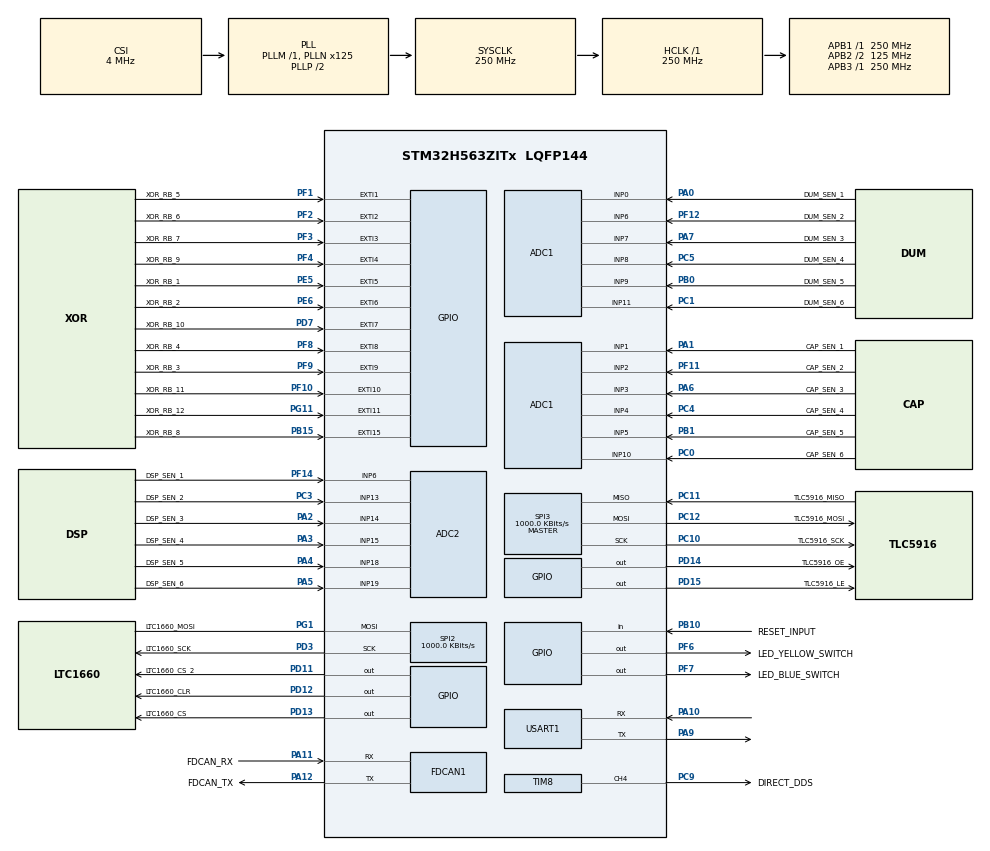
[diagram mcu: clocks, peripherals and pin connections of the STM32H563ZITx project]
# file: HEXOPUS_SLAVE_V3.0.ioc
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ADC1.Channel-10\#ChannelRegularConversion=ADC_CHANNEL_2
ADC1.Channel-11\#ChannelRegularConversion=ADC_CHANNEL_6
ADC1.Channel-12\#ChannelRegularConversion=ADC_CHANNEL_3
ADC1.Channel-13\#ChannelRegularConversion=ADC_CHANNEL_7
ADC1.Channel-14\#ChannelRegularConversion=ADC_CHANNEL_4
ADC1.Channel-15\#ChannelRegularConversion=ADC_CHANNEL_8
ADC1.Channel-16\#ChannelRegularConversion=ADC_CHANNEL_5
ADC1.Channel-17\#ChannelRegularConversion=ADC_CHANNEL_9
ADC1.Channel-18\#ChannelRegularConversion=ADC_CHANNEL_10
ADC1.Channel-19\#ChannelRegularConversion=ADC_CHANNEL_11
ADC1.Channel-8\#ChannelRegularConversion=ADC_CHANNEL_1
ADC1.Channel-9\#ChannelRegularConversion=ADC_CHANNEL_0
ADC1.ClockPrescaler=ADC_CLOCK_ASYNC_DIV2
ADC1.ContinuousConvMode=ENABLE
ADC1.DMAContinuousRequests=ENABLE
ADC1.MonitoredBy-10\#ChannelRegularConversion=__NULL
ADC1.MonitoredBy-11\#ChannelRegularConversion=__NULL
ADC1.MonitoredBy-12\#ChannelRegularConversion=__NULL
ADC1.MonitoredBy-13\#ChannelRegularConversion=__NULL
ADC1.MonitoredBy-14\#ChannelRegularConversion=__NULL
ADC1.MonitoredBy-15\#ChannelRegularConversion=__NULL
ADC1.MonitoredBy-16\#ChannelRegularConversion=__NULL
ADC1.MonitoredBy-17\#ChannelRegularConversion=__NULL
ADC1.MonitoredBy-18\#ChannelRegularConversion=__NULL
ADC1.MonitoredBy-19\#ChannelRegularConversion=__NULL
ADC1.MonitoredBy-8\#ChannelRegularConversion=__NULL
ADC1.MonitoredBy-9\#ChannelRegularConversion=__NULL
ADC1.NbrOfConversion=12
ADC1.NbrOfConversionFlag=1
ADC1.OffsetNumber-10\#ChannelRegularConversion=ADC_OFFSET_NONE
ADC1.OffsetNumber-11\#ChannelRegularConversion=ADC_OFFSET_NONE
ADC1.OffsetNumber-12\#ChannelRegularConversion=ADC_OFFSET_NONE
ADC1.OffsetNumber-13\#ChannelRegularConversion=ADC_OFFSET_NONE
ADC1.OffsetNumber-14\#ChannelRegularConversion=ADC_OFFSET_NONE
ADC1.OffsetNumber-15\#ChannelRegularConversion=ADC_OFFSET_NONE
ADC1.OffsetNumber-16\#ChannelRegularConversion=ADC_OFFSET_NONE
ADC1.OffsetNumber-17\#ChannelRegularConversion=ADC_OFFSET_NONE
ADC1.OffsetNumber-18\#ChannelRegularConversion=ADC_OFFSET_NONE
ADC1.OffsetNumber-19\#ChannelRegularConversion=ADC_OFFSET_NONE
ADC1.OffsetNumber-8\#ChannelRegularConversion=ADC_OFFSET_NONE
ADC1.OffsetNumber-9\#ChannelRegularConversion=ADC_OFFSET_NONE
ADC1.Rank-10\#ChannelRegularConversion=3
ADC1.Rank-11\#ChannelRegularConversion=4
ADC1.Rank-12\#ChannelRegularConversion=5
ADC1.Rank-13\#ChannelRegularConversion=6
ADC1.Rank-14\#ChannelRegularConversion=7
ADC1.Rank-15\#ChannelRegularConversion=8
ADC1.Rank-16\#ChannelRegularConversion=9
ADC1.Rank-17\#ChannelRegularConversion=10
ADC1.Rank-18\#ChannelRegularConversion=11
ADC1.Rank-19\#ChannelRegularConversion=12
ADC1.Rank-8\#ChannelRegularConversion=1
ADC1.Rank-9\#ChannelRegularConversion=2
ADC1.SamplingTime-10\#ChannelRegularConversion=ADC_SAMPLETIME_92CYCLES_5
ADC1.SamplingTime-11\#ChannelRegularConversion=ADC_SAMPLETIME_92CYCLES_5
ADC1.SamplingTime-12\#ChannelRegularConversion=ADC_SAMPLETIME_92CYCLES_5
ADC1.SamplingTime-13\#ChannelRegularConversion=ADC_SAMPLETIME_92CYCLES_5
ADC1.SamplingTime-14\#ChannelRegularConversion=ADC_SAMPLETIME_92CYCLES_5
ADC1.SamplingTime-15\#ChannelRegularConversion=ADC_SAMPLETIME_92CYCLES_5
ADC1.SamplingTime-16\#ChannelRegularConversion=ADC_SAMPLETIME_92CYCLES_5
ADC1.SamplingTime-17\#ChannelRegularConversion=ADC_SAMPLETIME_92CYCLES_5
ADC1.SamplingTime-18\#ChannelRegularConversion=ADC_SAMPLETIME_92CYCLES_5
ADC1.SamplingTime-19\#ChannelRegularConversion=ADC_SAMPLETIME_92CYCLES_5
ADC1.SamplingTime-8\#ChannelRegularConversion=ADC_SAMPLETIME_92CYCLES_5
ADC1.SamplingTime-9\#ChannelRegularConversion=ADC_SAMPLETIME_92CYCLES_5
ADC1.master=1
ADC2.Channel-18\#ChannelRegularConversion=ADC_CHANNEL_6
ADC2.Channel-19\#ChannelRegularConversion=ADC_CHANNEL_13
ADC2.Channel-20\#ChannelRegularConversion=ADC_CHANNEL_14
ADC2.Channel-21\#ChannelRegularConversion=ADC_CHANNEL_15
ADC2.Channel-22\#ChannelRegularConversion=ADC_CHANNEL_18
ADC2.Channel-23\#ChannelRegularConversion=ADC_CHANNEL_19
ADC2.ClockPrescaler=ADC_CLOCK_ASYNC_DIV2
ADC2.ContinuousConvMode=ENABLE
ADC2.DMAContinuousRequests=ENABLE
ADC2.MonitoredBy-18\#ChannelRegularConversion=__NULL
ADC2.MonitoredBy-19\#ChannelRegularConversion=__NULL
ADC2.MonitoredBy-20\#ChannelRegularConversion=__NULL
ADC2.MonitoredBy-21\#ChannelRegularConversion=__NULL
ADC2.MonitoredBy-22\#ChannelRegularConversion=__NULL
ADC2.MonitoredBy-23\#ChannelRegularConversion=__NULL
ADC2.NbrOfConversion=6
ADC2.NbrOfConversionFlag=1
ADC2.OffsetNumber-18\#ChannelRegularConversion=ADC_OFFSET_NONE
ADC2.OffsetNumber-19\#ChannelRegularConversion=ADC_OFFSET_NONE
ADC2.OffsetNumber-20\#ChannelRegularConversion=ADC_OFFSET_NONE
ADC2.OffsetNumber-21\#ChannelRegularConversion=ADC_OFFSET_NONE
ADC2.OffsetNumber-22\#ChannelRegularConversion=ADC_OFFSET_NONE
ADC2.OffsetNumber-23\#ChannelRegularConversion=ADC_OFFSET_NONE
ADC2.Rank-18\#ChannelRegularConversion=1
ADC2.Rank-19\#ChannelRegularConversion=2
ADC2.Rank-20\#ChannelRegularConversion=3
ADC2.Rank-21\#ChannelRegularConversion=4
ADC2.Rank-22\#ChannelRegularConversion=5
ADC2.Rank-23\#ChannelRegularConversion=6
ADC2.SamplingTime-18\#ChannelRegularConversion=ADC_SAMPLETIME_92CYCLES_5
ADC2.SamplingTime-19\#ChannelRegularConversion=ADC_SAMPLETIME_92CYCLES_5
ADC2.SamplingTime-20\#ChannelRegularConversion=ADC_SAMPLETIME_92CYCLES_5
ADC2.SamplingTime-21\#ChannelRegularConversion=ADC_SAMPLETIME_92CYCLES_5
ADC2.SamplingTime-22\#ChannelRegularConversion=ADC_SAMPLETIME_92CYCLES_5
ADC2.SamplingTime-23\#ChannelRegularConversion=ADC_SAMPLETIME_92CYCLES_5
BOOTPATH.BootPathName=LEGACY
BOOTPATH.UserSelectedBootPath=LEGACY
CORTEX_M33_NS.userName=CORTEX_M33
FDCAN1.AutoRetransmission=ENABLE
FDCAN1.CalculateBaudRateNominal=250000
FDCAN1.CalculateTimeBitNominal=4000
FDCAN1.CalculateTimeQuantumNominal=40.0
FDCAN1.ClockDivider=FDCAN_CLOCK_DIV1
FDCAN1.FrameFormat=FDCAN_FRAME_FD_NO_BRS
FDCAN1.NominalPrescaler=2
FDCAN1.NominalSyncJumpWidth=20
FDCAN1.NominalTimeSeg1=79
FDCAN1.NominalTimeSeg2=20
FDCAN1.StdFiltersNbr=1
FDCAN1.TransmitPause=ENABLE
GPDMA1.CIRCULARMODE_GPDMACH7=ENABLE
GPDMA1.DESTDATAWIDTH_GPDMACH7=DMA_DEST_DATAWIDTH_WORD
GPDMA1.DESTINC_GPDMACH7=DMA_DINC_INCREMENTED
GPDMA1.IPHANDLE_GPDMACH7-SIMPLEREQUEST_GPDMACH7=__NULL
GPDMA1.REQUEST_GPDMACH7=GPDMA1_REQUEST_ADC1
GPDMA1.SRCDATAWIDTH_GPDMACH7=DMA_SRC_DATAWIDTH_HALFWORD
GPDMA2.CIRCULARMODE_GPDMACH7=ENABLE
GPDMA2.DESTDATAWIDTH_GPDMACH7=DMA_DEST_DATAWIDTH_WORD
GPDMA2.DESTINC_GPDMACH7=DMA_DINC_INCREMENTED
GPDMA2.IPHANDLE_GPDMACH7-SIMPLEREQUEST_GPDMACH7=__NULL
GPDMA2.REQUEST_GPDMACH7=GPDMA2_REQUEST_ADC2
GPDMA2.SRCDATAWIDTH_GPDMACH7=DMA_SRC_DATAWIDTH_HALFWORD
Mcu.Family=STM32H5
Mcu.Name=STM32H563ZITx
Mcu.Package=LQFP144
NVIC.FDCAN1_IT0_IRQn=true\:0\:0\:false\:false\:true\:true\:true\:true
NVIC.GPDMA1_Channel7_IRQn=true\:0\:0\:false\:false\:true\:false\:true\:true
NVIC.GPDMA2_Channel7_IRQn=true\:0\:0\:false\:false\:true\:false\:true\:true
NVIC.PriorityGroup=NVIC_PRIORITYGROUP_4
NVIC.TIM12_IRQn=true\:15\:0\:true\:false\:true\:true\:true\:true
NVIC.TIM2_IRQn=true\:1\:0\:true\:false\:true\:true\:true\:true
NVIC.TIM3_IRQn=true\:0\:0\:false\:false\:true\:true\:true\:true
NVIC.TIM4_IRQn=true\:3\:0\:true\:false\:true\:true\:true\:true
NVIC.TIM5_IRQn=true\:2\:0\:true\:false\:true\:true\:true\:true
NVIC.USART1_IRQn=true\:4\:0\:true\:false\:true\:true\:true\:true
PA0.GPIO_Label=DUM_SEN_1
PA0.Signal=ADCx_INP0
PA1.GPIO_Label=CAP_SEN_1
PA1.Signal=ADCx_INP1
PA10.Mode=Asynchronous
PA10.Signal=USART1_RX
PA11.GPIO_Label=FDCAN_RX
PA11.Mode=FDCAN_Activate
PA11.Signal=FDCAN1_RX
PA12.GPIO_Label=FDCAN_TX
PA12.Mode=FDCAN_Activate
PA12.Signal=FDCAN1_TX
PA2.GPIO_Label=DSP_SEN_3
PA2.Signal=ADCx_INP14
PA3.GPIO_Label=DSP_SEN_4
PA3.Signal=ADCx_INP15
PA4.GPIO_Label=DSP_SEN_5
PA4.Signal=ADCx_INP18
PA5.GPIO_Label=DSP_SEN_6
PA5.Signal=ADCx_INP19
PA6.GPIO_Label=CAP_SEN_3
PA6.Signal=ADCx_INP3
PA7.GPIO_Label=DUM_SEN_3
PA7.Signal=ADCx_INP7
PA9.Mode=Asynchronous
PA9.Signal=USART1_TX
PB0.GPIO_Label=DUM_SEN_5
PB0.Signal=ADCx_INP9
PB1.GPIO_Label=CAP_SEN_5
PB1.Signal=ADCx_INP5
PB10.GPIO_Label=RESET_INPUT
PB10.Signal=GPIO_Input
PB12.GPIO_Label=FDCAN_AUX_RX
PB12.Signal=FDCAN2_RX
PB15.GPIO_Label=XOR_RB_8
PB15.Signal=GPXTI15
PC0.GPIO_Label=CAP_SEN_6
PC0.Signal=ADCx_INP10
PC1.GPIO_Label=DUM_SEN_6
PC1.Signal=ADCx_INP11
PC10.GPIO_Label=TLC5916_SCK
PC10.Mode=Full_Duplex_Master
PC10.Signal=SPI3_SCK
PC11.GPIO_Label=TLC5916_MISO
PC11.Mode=Full_Duplex_Master
PC11.Signal=SPI3_MISO
PC12.GPIO_Label=TLC5916_MOSI
PC12.Mode=Full_Duplex_Master
PC12.Signal=SPI3_MOSI
PC3.GPIO_Label=DSP_SEN_2
PC3.Signal=ADCx_INP13
PC4.GPIO_Label=CAP_SEN_4
PC4.Signal=ADCx_INP4
PC5.GPIO_Label=DUM_SEN_4
PC5.Signal=ADCx_INP8
PC9.GPIO_Label=DIRECT_DDS
PC9.GPIO_Speed=GPIO_SPEED_FREQ_VERY_HIGH
PC9.Signal=S_TIM8_CH4
PD11.GPIO_Label=LTC1660_CS_2
PD11.PinState=GPIO_PIN_RESET
PD11.Signal=GPIO_Output
PD12.GPIO_Label=LTC1660_CLR
PD12.PinState=GPIO_PIN_SET
PD12.Signal=GPIO_Output
PD13.GPIO_Label=LTC1660_CS
PD13.Signal=GPIO_Output
PD14.GPIO_Label=TLC5916_OE
PD14.Signal=GPIO_Output
PD15.GPIO_Label=TLC5916_LE
PD15.Signal=GPIO_Output
PD3.GPIO_Label=LTC1660_SCK
PD3.GPIO_PuPd=GPIO_PULLDOWN
PD3.GPIO_Speed=GPIO_SPEED_FREQ_VERY_HIGH
PD3.Mode=Simplex_Bidirectional_Master
PD3.Signal=SPI2_SCK
PD7.GPIO_Label=XOR_RB_10
PD7.Signal=GPXTI7
PE5.GPIO_Label=XOR_RB_1
PE5.Signal=GPXTI5
PE6.GPIO_Label=XOR_RB_2
PE6.Signal=GPXTI6
PF1.GPIO_Label=XOR_RB_5
PF1.Signal=GPXTI1
PF10.GPIO_Label=XOR_RB_11
PF10.Signal=GPXTI10
PF11.GPIO_Label=CAP_SEN_2
PF11.Mode=IN2-Single-Ended
PF11.Signal=ADC1_INP2
PF12.GPIO_Label=DUM_SEN_2
PF12.Mode=IN6-Single-Ended
PF12.Signal=ADC1_INP6
PF14.GPIO_Label=DSP_SEN_1
PF14.Mode=IN6-Single-Ended
PF14.Signal=ADC2_INP6
PF2.GPIO_Label=XOR_RB_6
PF2.Signal=GPXTI2
PF3.GPIO_Label=XOR_RB_7
PF3.Signal=GPXTI3
PF4.GPIO_Label=XOR_RB_9
PF4.Signal=GPXTI4
PF6.GPIO_Label=LED_YELLOW_SWITCH
PF6.Signal=GPIO_Output
PF7.GPIO_Label=LED_BLUE_SWITCH
PF7.Signal=GPIO_Output
PF8.GPIO_Label=XOR_RB_4
PF8.Signal=GPXTI8
PF9.GPIO_Label=XOR_RB_3
PF9.Signal=GPXTI9
PG1.GPIO_Label=LTC1660_MOSI
PG1.GPIO_PuPd=GPIO_PULLDOWN
PG1.GPIO_Speed=GPIO_SPEED_FREQ_VERY_HIGH
PG1.Mode=Simplex_Bidirectional_Master
PG1.Signal=SPI2_MOSI
PG11.GPIO_Label=XOR_RB_12
PG11.Signal=GPXTI11
ProjectManager.HeapSize=0x200
ProjectManager.StackSize=0x400
ProjectManager.TargetToolchain=STM32CubeIDE
RCC.ADCCLockSelection=RCC_ADCDACCLKSOURCE_HSI
RCC.ADCFreq_Value=64000000
RCC.AHBFreq_Value=250000000
RCC.APB1Freq_Value=250000000
RCC.APB1TimFreq_Value=250000000
RCC.APB2CLKDivider=RCC_HCLK_DIV2
RCC.APB2Freq_Value=125000000
RCC.APB2TimFreq_Value=250000000
RCC.APB3Freq_Value=250000000
RCC.CKPERSourceSelection=RCC_CLKPSOURCE_HSI
RCC.CSI_VALUE=4000000
RCC.CortexFreq_Value=250000000
RCC.DACLowPowerCLockSelection=RCC_DACLPCLKSOURCE_LSI
RCC.DATA_CACHE_ENABLE=1
RCC.EPOD_VALUE=4000000
RCC.FDCANClockSelection=RCC_FDCANCLKSOURCE_PLL2Q
RCC.HCLKFreq_Value=250000000
RCC.HSE_VALUE=25000000
RCC.HSI48_VALUE=48000000
RCC.HSIDiv=RCC_HSI_DIV1
RCC.HSI_VALUE=64000000
RCC.I2C1CLockSelection=RCC_I2C1CLKSOURCE_CSI
RCC.INSTRUCTION_CACHE_ENABLE=1
RCC.LSE_VALUE=32768
RCC.LSIRC_VALUE=32000
RCC.PLL2FRACN=0
RCC.PLL2N=125
RCC.PLL2P=5
RCC.PLL2Q=10
RCC.PLL2R=4
RCC.PLL2_VCI_Range-AdvancedSettings=RCC_PLL2_VCIRANGE_3
RCC.PLL3M=4
RCC.PLL3N=128
RCC.PLL3P=64
RCC.PLL3Q=4
RCC.PLL3R=4
RCC.PLLFRACN=0
RCC.PLLN=125
RCC.PREFETCH_ENABLE=1
RCC.PWREXT_OverDrive=PWREXT_OverDrive_DESACTIVATED
RCC.SDMMC1ClockSelection=RCC_SDMMC1CLKSOURCE_PLL1Q
RCC.SPI1CLockSelection=RCC_SPI1CLKSOURCE_PLL3P
RCC.SPI2CLockSelection=RCC_SPI2CLKSOURCE_PLL3P
RCC.SPI3CLockSelection=RCC_SPI3CLKSOURCE_PLL3P
RCC.SYSCLKFreq_VALUE=250000000
RCC.SYSCLKSource=RCC_SYSCLKSOURCE_PLLCLK
RCC.UART5CLockSelection=RCC_UART5CLKSOURCE_CSI
RCC.USART1CLockSelection=RCC_USART1CLKSOURCE_CSI
RCC.USBFreq_Value=48000000
RCC.VCOOutputFreq_Value=500000000
SH.ADCx_INP0.0=ADC1_INP0,IN0-Single-Ended
SH.ADCx_INP1.0=ADC1_INP1,IN1-Single-Ended
SH.ADCx_INP10.0=ADC1_INP10,IN10-Single-Ended
SH.ADCx_INP11.0=ADC1_INP11,IN11-Single-Ended
SH.ADCx_INP13.0=ADC2_INP13,IN13-Single-Ended
SH.ADCx_INP14.0=ADC2_INP14,IN14-Single-Ended
SH.ADCx_INP15.0=ADC2_INP15,IN15-Single-Ended
SH.ADCx_INP18.0=ADC2_INP18,IN18-Single-Ended
SH.ADCx_INP19.0=ADC2_INP19,IN19-Single-Ended
SH.ADCx_INP3.0=ADC1_INP3,IN3-Single-Ended
SH.ADCx_INP4.0=ADC1_INP4,IN4-Single-Ended
SH.ADCx_INP5.0=ADC1_INP5,IN5-Single-Ended
SH.ADCx_INP7.0=ADC1_INP7,IN7-Single-Ended
SH.ADCx_INP8.0=ADC1_INP8,IN8-Single-Ended
SH.ADCx_INP9.0=ADC1_INP9,IN9-Single-Ended
SH.S_TIM8_CH4.0=TIM8_CH4,PWM Generation4 CH4
SPI2.BaudRatePrescaler=SPI_BAUDRATEPRESCALER_2
SPI2.CalculateBaudRate=1000.0 KBits/s
SPI2.DataSize=SPI_DATASIZE_16BIT
SPI2.Direction=SPI_DIRECTION_1LINE
SPI2.Mode=SPI_MODE_MASTER
SPI2.NSSPMode=SPI_NSS_PULSE_DISABLE
SPI2.VirtualType=VM_MASTER
SPI3.CalculateBaudRate=1000.0 KBits/s
SPI3.DataSize=SPI_DATASIZE_8BIT
SPI3.Direction=SPI_DIRECTION_2LINES
SPI3.Mode=SPI_MODE_MASTER
SPI3.NSSPMode=SPI_NSS_PULSE_DISABLE
SPI3.VirtualType=VM_MASTER
TIM12.AutoReloadPreload=TIM_AUTORELOAD_PRELOAD_ENABLE
TIM12.PeriodNoDither=49999
TIM12.Prescaler=2499
TIM2.AutoReloadPreload=TIM_AUTORELOAD_PRELOAD_ENABLE
TIM2.ClockDivision=TIM_CLOCKDIVISION_DIV1
TIM2.PeriodNoDither=199
TIM2.Prescaler=99
TIM3.AutoReloadPreload=TIM_AUTORELOAD_PRELOAD_ENABLE
TIM3.ClockDivision=TIM_CLOCKDIVISION_DIV1
TIM3.PeriodNoDither=124
TIM3.Prescaler=49
TIM4.AutoReloadPreload=TIM_AUTORELOAD_PRELOAD_ENABLE
TIM4.PeriodNoDither=499
TIM4.Prescaler=2499
TIM5.AutoReloadPreload=TIM_AUTORELOAD_PRELOAD_ENABLE
TIM5.PeriodNoDither=499
TIM5.Prescaler=499
TIM8.AutoReloadPreload=TIM_AUTORELOAD_PRELOAD_ENABLE
TIM8.Channel-PWM\ Generation4\ CH4=TIM_CHANNEL_4
TIM8.PeriodNoDither=833
TIM8.PulseNoDither_4=417
USART1.VirtualMode-Asynchronous=VM_ASYNC
VP_BOOTPATH_VS_BOOTPATH.Mode=BP_Activate
VP_CORTEX_M33_NS_VS_Hclk.Mode=Hclk_Mode
VP_CRC_VS_CRC.Mode=CRC_Activate
VP_FLASH_SIG_Activate_FlashIP.Mode=Activate_FlashIP
VP_GPDMA1_VS_GPDMACH7.Mode=SIMPLEREQUEST_GPDMACH7
VP_GPDMA2_VS_GPDMACH7.Mode=SIMPLEREQUEST_GPDMACH7
VP_ICACHE_VS_ICACHE.Mode=DirectMappedCache
VP_MEMORYMAP_VS_MEMORYMAP.Mode=CurAppReg
VP_PWR_VS_LPOM.Mode=PowerOptimisation
VP_PWR_VS_SECSignals.Mode=Security/Privilege
VP_TIM12_VS_ClockSourceINT.Mode=Internal
VP_TIM2_VS_ClockSourceINT.Mode=Internal
VP_TIM3_VS_ClockSourceINT.Mode=Internal
VP_TIM4_VS_ClockSourceINT.Mode=Internal
VP_TIM5_VS_ClockSourceINT.Mode=Internal
board=custom

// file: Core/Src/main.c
/* USER CODE BEGIN Header */
/**
  ******************************************************************************
  * @file           : main.c
  * @brief          : Main program body
  ******************************************************************************
  * @attention
  *
  * Copyright (c) 2026 STMicroelectronics.
  * All rights reserved.
  *
  * This software is licensed under terms that can be found in the LICENSE file
  * in the root directory of this software component.
  * If no LICENSE file comes with this software, it is provided AS-IS.
  *
  ******************************************************************************
  */
/* USER CODE END Header */
#include "main.h"
#include "adc.h"
#include "crc.h"
#include "fdcan.h"
#include "flash.h"
#include "gpdma.h"
#include "icache.h"
#include "spi.h"
#include "tim.h"
#include "usart.h"
#include "gpio.h"

/* USER CODE BEGIN Includes */
#include "app.h"
#include "callbacks.h"
/* USER CODE END Includes */

void SystemClock_Config(void);
void PeriphCommonClock_Config(void);

int main(void)
{

  /* MCU Configuration--------------------------------------------------------*/

  /* Reset of all peripherals, Initializes the Flash interface and the Systick. */
  HAL_Init();

  /* Configure the system clock */
  SystemClock_Config();

  /* Configure the peripherals common clocks */
  PeriphCommonClock_Config();

  /* Initialize all configured peripherals */
  MX_GPIO_Init();
  MX_GPDMA2_Init();
  MX_GPDMA1_Init();
  MX_FDCAN1_Init();
  MX_SPI3_Init();
  MX_USART1_UART_Init();
  MX_TIM2_Init();
  MX_ICACHE_Init();
  MX_SPI2_Init();
  MX_TIM4_Init();
  MX_TIM5_Init();
  MX_TIM3_Init();
  MX_FLASH_Init();
  MX_TIM12_Init();
  MX_ADC1_Init();
  MX_ADC2_Init();
  MX_TIM8_Init();
  MX_CRC_Init();
  /* USER CODE BEGIN 2 */
  app_init();
  /* USER CODE END 2 */

  /* Infinite loop */
  /* USER CODE BEGIN WHILE */
	app_main();
  while (1)
  {
    /* USER CODE END WHILE */

  }
}

void SystemClock_Config(void)
{
  RCC_OscInitTypeDef RCC_OscInitStruct = {0};
  RCC_ClkInitTypeDef RCC_ClkInitStruct = {0};

  /** Configure the main internal regulator output voltage
  */
  __HAL_PWR_VOLTAGESCALING_CONFIG(PWR_REGULATOR_VOLTAGE_SCALE0);

  while(!__HAL_PWR_GET_FLAG(PWR_FLAG_VOSRDY)) {}

  /** Initializes the RCC Oscillators according to the specified parameters
  * in the RCC_OscInitTypeDef structure.
  */
  RCC_OscInitStruct.OscillatorType = RCC_OSCILLATORTYPE_HSI|RCC_OSCILLATORTYPE_CSI;
  RCC_OscInitStruct.HSIState = RCC_HSI_ON;
  RCC_OscInitStruct.HSIDiv = RCC_HSI_DIV1;
  RCC_OscInitStruct.HSICalibrationValue = RCC_HSICALIBRATION_DEFAULT;
  RCC_OscInitStruct.CSIState = RCC_CSI_ON;
  RCC_OscInitStruct.CSICalibrationValue = RCC_CSICALIBRATION_DEFAULT;
  RCC_OscInitStruct.PLL.PLLState = RCC_PLL_ON;
  RCC_OscInitStruct.PLL.PLLSource = RCC_PLL1_SOURCE_CSI;
  RCC_OscInitStruct.PLL.PLLM = 1;
  RCC_OscInitStruct.PLL.PLLN = 125;
  RCC_OscInitStruct.PLL.PLLP = 2;
  RCC_OscInitStruct.PLL.PLLQ = 2;
  RCC_OscInitStruct.PLL.PLLR = 2;
  RCC_OscInitStruct.PLL.PLLRGE = RCC_PLL1_VCIRANGE_2;
  RCC_OscInitStruct.PLL.PLLVCOSEL = RCC_PLL1_VCORANGE_WIDE;
  RCC_OscInitStruct.PLL.PLLFRACN = 0;
  if (HAL_RCC_OscConfig(&RCC_OscInitStruct) != HAL_OK)
  {
    Error_Handler();
  }

  /** Initializes the CPU, AHB and APB buses clocks
  */
  RCC_ClkInitStruct.ClockType = RCC_CLOCKTYPE_HCLK|RCC_CLOCKTYPE_SYSCLK
                              |RCC_CLOCKTYPE_PCLK1|RCC_CLOCKTYPE_PCLK2
                              |RCC_CLOCKTYPE_PCLK3;
  RCC_ClkInitStruct.SYSCLKSource = RCC_SYSCLKSOURCE_PLLCLK;
  RCC_ClkInitStruct.AHBCLKDivider = RCC_SYSCLK_DIV1;
  RCC_ClkInitStruct.APB1CLKDivider = RCC_HCLK_DIV1;
  RCC_ClkInitStruct.APB2CLKDivider = RCC_HCLK_DIV2;
  RCC_ClkInitStruct.APB3CLKDivider = RCC_HCLK_DIV1;

  if (HAL_RCC_ClockConfig(&RCC_ClkInitStruct, FLASH_LATENCY_5) != HAL_OK)
  {
    Error_Handler();
  }

  /** Configure the programming delay
  */
  __HAL_FLASH_SET_PROGRAM_DELAY(FLASH_PROGRAMMING_DELAY_2);
}

void PeriphCommonClock_Config(void)
{
  RCC_PeriphCLKInitTypeDef PeriphClkInitStruct = {0};

  /** Initializes the peripherals clock
  */
  PeriphClkInitStruct.PeriphClockSelection = RCC_PERIPHCLK_SPI2|RCC_PERIPHCLK_SPI3;
  PeriphClkInitStruct.PLL3.PLL3Source = RCC_PLL3_SOURCE_CSI;
  PeriphClkInitStruct.PLL3.PLL3M = 4;
  PeriphClkInitStruct.PLL3.PLL3N = 128;
  PeriphClkInitStruct.PLL3.PLL3P = 64;
  PeriphClkInitStruct.PLL3.PLL3Q = 4;
  PeriphClkInitStruct.PLL3.PLL3R = 4;
  PeriphClkInitStruct.PLL3.PLL3RGE = RCC_PLL3_VCIRANGE_3;
  PeriphClkInitStruct.PLL3.PLL3VCOSEL = RCC_PLL3_VCORANGE_WIDE;
  PeriphClkInitStruct.PLL3.PLL3FRACN = 0;
  PeriphClkInitStruct.PLL3.PLL3ClockOut = RCC_PLL3_DIVP;
  PeriphClkInitStruct.Spi2ClockSelection = RCC_SPI2CLKSOURCE_PLL3P;
  PeriphClkInitStruct.Spi3ClockSelection = RCC_SPI3CLKSOURCE_PLL3P;
  if (HAL_RCCEx_PeriphCLKConfig(&PeriphClkInitStruct) != HAL_OK)
  {
    Error_Handler();
  }
}

void Error_Handler(void)
{
  __disable_irq();
  while (1)
  {
  }
}
